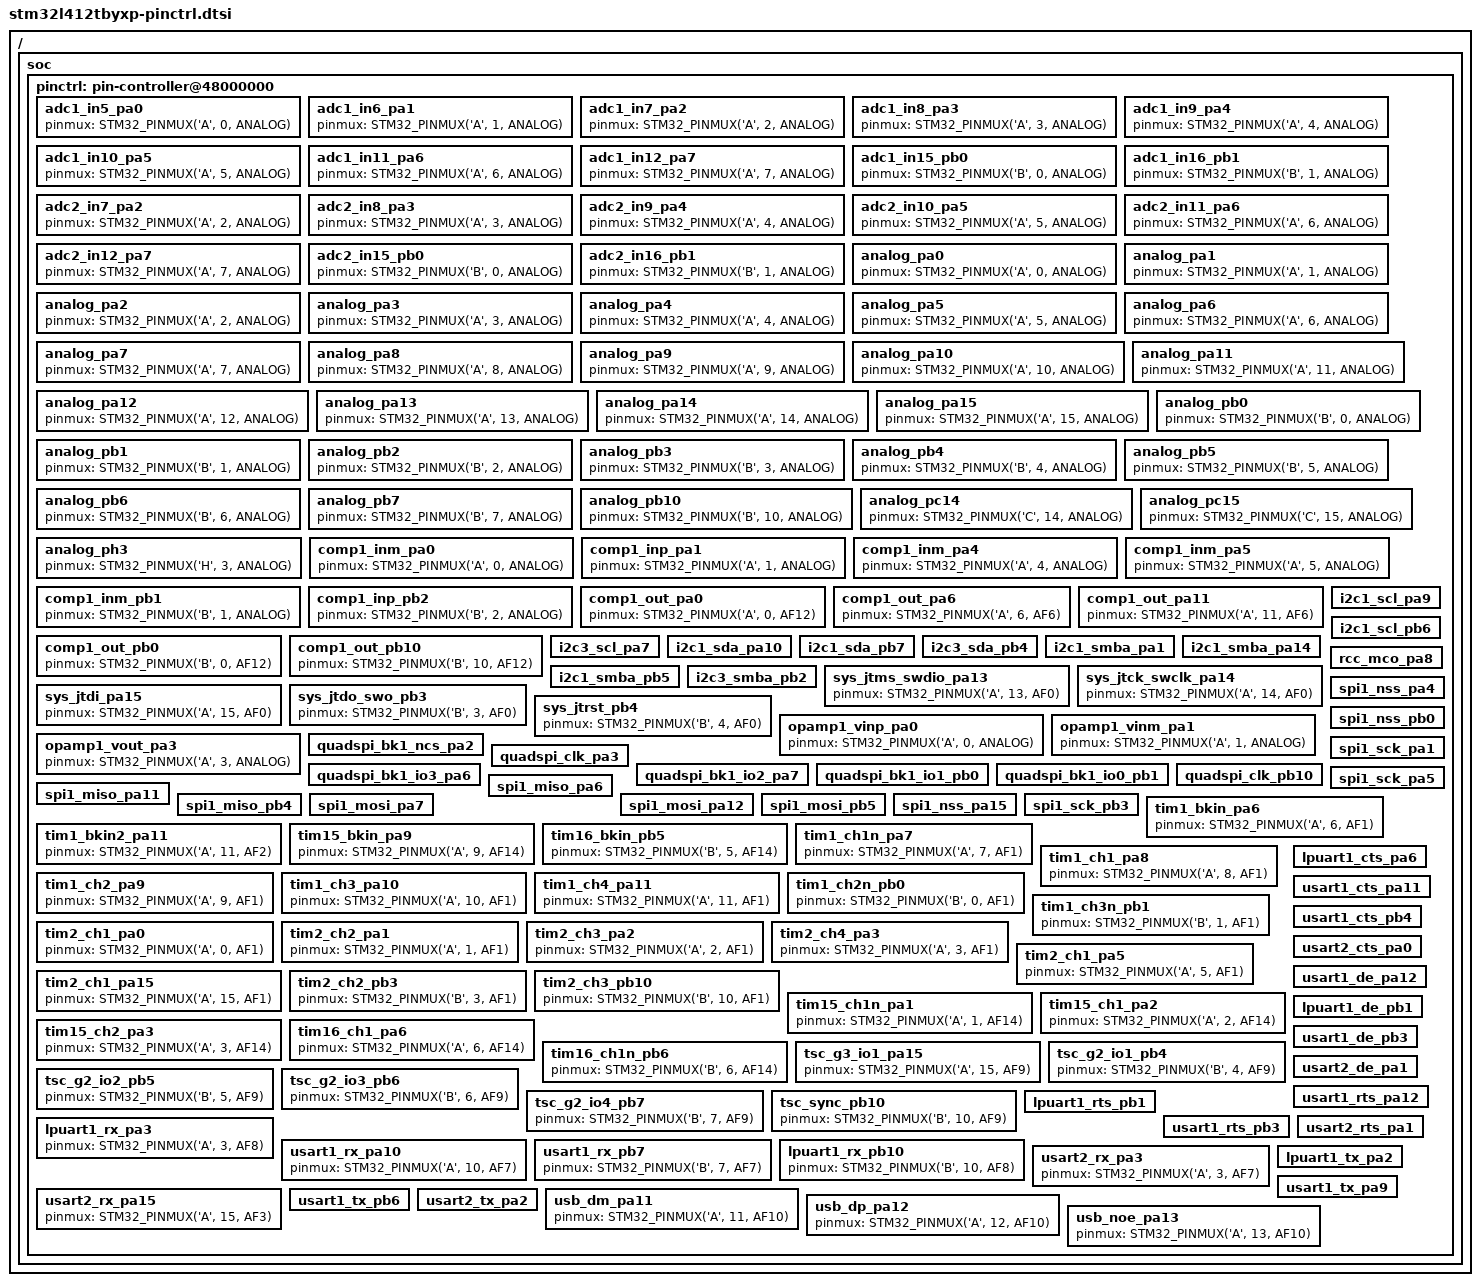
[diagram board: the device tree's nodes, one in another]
/*
 * NOTE: Autogenerated file using genpinctrl.py
 *
 * SPDX-License-Identifier: Apache-2.0
 */

#include <zephyr/dt-bindings/pinctrl/stm32-pinctrl.h>

/ {
	soc {
		pinctrl: pin-controller@48000000 {

			/* ADC_IN / ADC_INN / ADC_INP */

			/omit-if-no-ref/ adc1_in5_pa0: adc1_in5_pa0 {
				pinmux = <STM32_PINMUX('A', 0, ANALOG)>;
			};

			/omit-if-no-ref/ adc1_in6_pa1: adc1_in6_pa1 {
				pinmux = <STM32_PINMUX('A', 1, ANALOG)>;
			};

			/omit-if-no-ref/ adc1_in7_pa2: adc1_in7_pa2 {
				pinmux = <STM32_PINMUX('A', 2, ANALOG)>;
			};

			/omit-if-no-ref/ adc1_in8_pa3: adc1_in8_pa3 {
				pinmux = <STM32_PINMUX('A', 3, ANALOG)>;
			};

			/omit-if-no-ref/ adc1_in9_pa4: adc1_in9_pa4 {
				pinmux = <STM32_PINMUX('A', 4, ANALOG)>;
			};

			/omit-if-no-ref/ adc1_in10_pa5: adc1_in10_pa5 {
				pinmux = <STM32_PINMUX('A', 5, ANALOG)>;
			};

			/omit-if-no-ref/ adc1_in11_pa6: adc1_in11_pa6 {
				pinmux = <STM32_PINMUX('A', 6, ANALOG)>;
			};

			/omit-if-no-ref/ adc1_in12_pa7: adc1_in12_pa7 {
				pinmux = <STM32_PINMUX('A', 7, ANALOG)>;
			};

			/omit-if-no-ref/ adc1_in15_pb0: adc1_in15_pb0 {
				pinmux = <STM32_PINMUX('B', 0, ANALOG)>;
			};

			/omit-if-no-ref/ adc1_in16_pb1: adc1_in16_pb1 {
				pinmux = <STM32_PINMUX('B', 1, ANALOG)>;
			};

			/omit-if-no-ref/ adc2_in7_pa2: adc2_in7_pa2 {
				pinmux = <STM32_PINMUX('A', 2, ANALOG)>;
			};

			/omit-if-no-ref/ adc2_in8_pa3: adc2_in8_pa3 {
				pinmux = <STM32_PINMUX('A', 3, ANALOG)>;
			};

			/omit-if-no-ref/ adc2_in9_pa4: adc2_in9_pa4 {
				pinmux = <STM32_PINMUX('A', 4, ANALOG)>;
			};

			/omit-if-no-ref/ adc2_in10_pa5: adc2_in10_pa5 {
				pinmux = <STM32_PINMUX('A', 5, ANALOG)>;
			};

			/omit-if-no-ref/ adc2_in11_pa6: adc2_in11_pa6 {
				pinmux = <STM32_PINMUX('A', 6, ANALOG)>;
			};

			/omit-if-no-ref/ adc2_in12_pa7: adc2_in12_pa7 {
				pinmux = <STM32_PINMUX('A', 7, ANALOG)>;
			};

			/omit-if-no-ref/ adc2_in15_pb0: adc2_in15_pb0 {
				pinmux = <STM32_PINMUX('B', 0, ANALOG)>;
			};

			/omit-if-no-ref/ adc2_in16_pb1: adc2_in16_pb1 {
				pinmux = <STM32_PINMUX('B', 1, ANALOG)>;
			};

			/* Analog */

			/omit-if-no-ref/ analog_pa0: analog_pa0 {
				pinmux = <STM32_PINMUX('A', 0, ANALOG)>;
			};

			/omit-if-no-ref/ analog_pa1: analog_pa1 {
				pinmux = <STM32_PINMUX('A', 1, ANALOG)>;
			};

			/omit-if-no-ref/ analog_pa2: analog_pa2 {
				pinmux = <STM32_PINMUX('A', 2, ANALOG)>;
			};

			/omit-if-no-ref/ analog_pa3: analog_pa3 {
				pinmux = <STM32_PINMUX('A', 3, ANALOG)>;
			};

			/omit-if-no-ref/ analog_pa4: analog_pa4 {
				pinmux = <STM32_PINMUX('A', 4, ANALOG)>;
			};

			/omit-if-no-ref/ analog_pa5: analog_pa5 {
				pinmux = <STM32_PINMUX('A', 5, ANALOG)>;
			};

			/omit-if-no-ref/ analog_pa6: analog_pa6 {
				pinmux = <STM32_PINMUX('A', 6, ANALOG)>;
			};

			/omit-if-no-ref/ analog_pa7: analog_pa7 {
				pinmux = <STM32_PINMUX('A', 7, ANALOG)>;
			};

			/omit-if-no-ref/ analog_pa8: analog_pa8 {
				pinmux = <STM32_PINMUX('A', 8, ANALOG)>;
			};

			/omit-if-no-ref/ analog_pa9: analog_pa9 {
				pinmux = <STM32_PINMUX('A', 9, ANALOG)>;
			};

			/omit-if-no-ref/ analog_pa10: analog_pa10 {
				pinmux = <STM32_PINMUX('A', 10, ANALOG)>;
			};

			/omit-if-no-ref/ analog_pa11: analog_pa11 {
				pinmux = <STM32_PINMUX('A', 11, ANALOG)>;
			};

			/omit-if-no-ref/ analog_pa12: analog_pa12 {
				pinmux = <STM32_PINMUX('A', 12, ANALOG)>;
			};

			/omit-if-no-ref/ analog_pa13: analog_pa13 {
				pinmux = <STM32_PINMUX('A', 13, ANALOG)>;
			};

			/omit-if-no-ref/ analog_pa14: analog_pa14 {
				pinmux = <STM32_PINMUX('A', 14, ANALOG)>;
			};

			/omit-if-no-ref/ analog_pa15: analog_pa15 {
				pinmux = <STM32_PINMUX('A', 15, ANALOG)>;
			};

			/omit-if-no-ref/ analog_pb0: analog_pb0 {
				pinmux = <STM32_PINMUX('B', 0, ANALOG)>;
			};

			/omit-if-no-ref/ analog_pb1: analog_pb1 {
				pinmux = <STM32_PINMUX('B', 1, ANALOG)>;
			};

			/omit-if-no-ref/ analog_pb2: analog_pb2 {
				pinmux = <STM32_PINMUX('B', 2, ANALOG)>;
			};

			/omit-if-no-ref/ analog_pb3: analog_pb3 {
				pinmux = <STM32_PINMUX('B', 3, ANALOG)>;
			};

			/omit-if-no-ref/ analog_pb4: analog_pb4 {
				pinmux = <STM32_PINMUX('B', 4, ANALOG)>;
			};

			/omit-if-no-ref/ analog_pb5: analog_pb5 {
				pinmux = <STM32_PINMUX('B', 5, ANALOG)>;
			};

			/omit-if-no-ref/ analog_pb6: analog_pb6 {
				pinmux = <STM32_PINMUX('B', 6, ANALOG)>;
			};

			/omit-if-no-ref/ analog_pb7: analog_pb7 {
				pinmux = <STM32_PINMUX('B', 7, ANALOG)>;
			};

			/omit-if-no-ref/ analog_pb10: analog_pb10 {
				pinmux = <STM32_PINMUX('B', 10, ANALOG)>;
			};

			/omit-if-no-ref/ analog_pc14: analog_pc14 {
				pinmux = <STM32_PINMUX('C', 14, ANALOG)>;
			};

			/omit-if-no-ref/ analog_pc15: analog_pc15 {
				pinmux = <STM32_PINMUX('C', 15, ANALOG)>;
			};

			/omit-if-no-ref/ analog_ph3: analog_ph3 {
				pinmux = <STM32_PINMUX('H', 3, ANALOG)>;
			};

			/* COMP_IN */

			/omit-if-no-ref/ comp1_inm_pa0: comp1_inm_pa0 {
				pinmux = <STM32_PINMUX('A', 0, ANALOG)>;
			};

			/omit-if-no-ref/ comp1_inp_pa1: comp1_inp_pa1 {
				pinmux = <STM32_PINMUX('A', 1, ANALOG)>;
			};

			/omit-if-no-ref/ comp1_inm_pa4: comp1_inm_pa4 {
				pinmux = <STM32_PINMUX('A', 4, ANALOG)>;
			};

			/omit-if-no-ref/ comp1_inm_pa5: comp1_inm_pa5 {
				pinmux = <STM32_PINMUX('A', 5, ANALOG)>;
			};

			/omit-if-no-ref/ comp1_inm_pb1: comp1_inm_pb1 {
				pinmux = <STM32_PINMUX('B', 1, ANALOG)>;
			};

			/omit-if-no-ref/ comp1_inp_pb2: comp1_inp_pb2 {
				pinmux = <STM32_PINMUX('B', 2, ANALOG)>;
			};

			/* COMP_OUT */

			/omit-if-no-ref/ comp1_out_pa0: comp1_out_pa0 {
				pinmux = <STM32_PINMUX('A', 0, AF12)>;
			};

			/omit-if-no-ref/ comp1_out_pa6: comp1_out_pa6 {
				pinmux = <STM32_PINMUX('A', 6, AF6)>;
			};

			/omit-if-no-ref/ comp1_out_pa11: comp1_out_pa11 {
				pinmux = <STM32_PINMUX('A', 11, AF6)>;
			};

			/omit-if-no-ref/ comp1_out_pb0: comp1_out_pb0 {
				pinmux = <STM32_PINMUX('B', 0, AF12)>;
			};

			/omit-if-no-ref/ comp1_out_pb10: comp1_out_pb10 {
				pinmux = <STM32_PINMUX('B', 10, AF12)>;
			};

			/* I2C_SCL */

			/omit-if-no-ref/ i2c1_scl_pa9: i2c1_scl_pa9 {
				pinmux = <STM32_PINMUX('A', 9, AF4)>;
				bias-pull-up;
				drive-open-drain;
			};

			/omit-if-no-ref/ i2c1_scl_pb6: i2c1_scl_pb6 {
				pinmux = <STM32_PINMUX('B', 6, AF4)>;
				bias-pull-up;
				drive-open-drain;
			};

			/omit-if-no-ref/ i2c3_scl_pa7: i2c3_scl_pa7 {
				pinmux = <STM32_PINMUX('A', 7, AF4)>;
				bias-pull-up;
				drive-open-drain;
			};

			/* I2C_SDA */

			/omit-if-no-ref/ i2c1_sda_pa10: i2c1_sda_pa10 {
				pinmux = <STM32_PINMUX('A', 10, AF4)>;
				bias-pull-up;
				drive-open-drain;
			};

			/omit-if-no-ref/ i2c1_sda_pb7: i2c1_sda_pb7 {
				pinmux = <STM32_PINMUX('B', 7, AF4)>;
				bias-pull-up;
				drive-open-drain;
			};

			/omit-if-no-ref/ i2c3_sda_pb4: i2c3_sda_pb4 {
				pinmux = <STM32_PINMUX('B', 4, AF4)>;
				bias-pull-up;
				drive-open-drain;
			};

			/* I2C_SMBA */

			/omit-if-no-ref/ i2c1_smba_pa1: i2c1_smba_pa1 {
				pinmux = <STM32_PINMUX('A', 1, AF4)>;
				bias-pull-up;
			};

			/omit-if-no-ref/ i2c1_smba_pa14: i2c1_smba_pa14 {
				pinmux = <STM32_PINMUX('A', 14, AF4)>;
				bias-pull-up;
			};

			/omit-if-no-ref/ i2c1_smba_pb5: i2c1_smba_pb5 {
				pinmux = <STM32_PINMUX('B', 5, AF4)>;
				bias-pull-up;
			};

			/omit-if-no-ref/ i2c3_smba_pb2: i2c3_smba_pb2 {
				pinmux = <STM32_PINMUX('B', 2, AF4)>;
				bias-pull-up;
			};

			/* JTAG PORT */

			/omit-if-no-ref/ sys_jtms_swdio_pa13: sys_jtms_swdio_pa13 {
				pinmux = <STM32_PINMUX('A', 13, AF0)>;
			};

			/omit-if-no-ref/ sys_jtck_swclk_pa14: sys_jtck_swclk_pa14 {
				pinmux = <STM32_PINMUX('A', 14, AF0)>;
			};

			/omit-if-no-ref/ sys_jtdi_pa15: sys_jtdi_pa15 {
				pinmux = <STM32_PINMUX('A', 15, AF0)>;
			};

			/omit-if-no-ref/ sys_jtdo_swo_pb3: sys_jtdo_swo_pb3 {
				pinmux = <STM32_PINMUX('B', 3, AF0)>;
			};

			/omit-if-no-ref/ sys_jtrst_pb4: sys_jtrst_pb4 {
				pinmux = <STM32_PINMUX('B', 4, AF0)>;
			};

			/* OPAMP */

			/omit-if-no-ref/ opamp1_vinp_pa0: opamp1_vinp_pa0 {
				pinmux = <STM32_PINMUX('A', 0, ANALOG)>;
			};

			/omit-if-no-ref/ opamp1_vinm_pa1: opamp1_vinm_pa1 {
				pinmux = <STM32_PINMUX('A', 1, ANALOG)>;
			};

			/omit-if-no-ref/ opamp1_vout_pa3: opamp1_vout_pa3 {
				pinmux = <STM32_PINMUX('A', 3, ANALOG)>;
			};

			/* QUADSPI */

			/omit-if-no-ref/ quadspi_bk1_ncs_pa2: quadspi_bk1_ncs_pa2 {
				pinmux = <STM32_PINMUX('A', 2, AF10)>;
				slew-rate = "very-high-speed";
			};

			/omit-if-no-ref/ quadspi_clk_pa3: quadspi_clk_pa3 {
				pinmux = <STM32_PINMUX('A', 3, AF10)>;
				slew-rate = "very-high-speed";
			};

			/omit-if-no-ref/ quadspi_bk1_io3_pa6: quadspi_bk1_io3_pa6 {
				pinmux = <STM32_PINMUX('A', 6, AF10)>;
				slew-rate = "very-high-speed";
			};

			/omit-if-no-ref/ quadspi_bk1_io2_pa7: quadspi_bk1_io2_pa7 {
				pinmux = <STM32_PINMUX('A', 7, AF10)>;
				slew-rate = "very-high-speed";
			};

			/omit-if-no-ref/ quadspi_bk1_io1_pb0: quadspi_bk1_io1_pb0 {
				pinmux = <STM32_PINMUX('B', 0, AF10)>;
				slew-rate = "very-high-speed";
			};

			/omit-if-no-ref/ quadspi_bk1_io0_pb1: quadspi_bk1_io0_pb1 {
				pinmux = <STM32_PINMUX('B', 1, AF10)>;
				slew-rate = "very-high-speed";
			};

			/omit-if-no-ref/ quadspi_clk_pb10: quadspi_clk_pb10 {
				pinmux = <STM32_PINMUX('B', 10, AF10)>;
				slew-rate = "very-high-speed";
			};

			/* RCC_MCO */

			/omit-if-no-ref/ rcc_mco_pa8: rcc_mco_pa8 {
				pinmux = <STM32_PINMUX('A', 8, AF0)>;
				slew-rate = "very-high-speed";
			};

			/* SPI_MISO */

			/omit-if-no-ref/ spi1_miso_pa6: spi1_miso_pa6 {
				pinmux = <STM32_PINMUX('A', 6, AF5)>;
				bias-pull-down;
			};

			/omit-if-no-ref/ spi1_miso_pa11: spi1_miso_pa11 {
				pinmux = <STM32_PINMUX('A', 11, AF5)>;
				bias-pull-down;
			};

			/omit-if-no-ref/ spi1_miso_pb4: spi1_miso_pb4 {
				pinmux = <STM32_PINMUX('B', 4, AF5)>;
				bias-pull-down;
			};

			/* SPI_MOSI */

			/omit-if-no-ref/ spi1_mosi_pa7: spi1_mosi_pa7 {
				pinmux = <STM32_PINMUX('A', 7, AF5)>;
				bias-pull-down;
			};

			/omit-if-no-ref/ spi1_mosi_pa12: spi1_mosi_pa12 {
				pinmux = <STM32_PINMUX('A', 12, AF5)>;
				bias-pull-down;
			};

			/omit-if-no-ref/ spi1_mosi_pb5: spi1_mosi_pb5 {
				pinmux = <STM32_PINMUX('B', 5, AF5)>;
				bias-pull-down;
			};

			/* SPI_NSS */

			/omit-if-no-ref/ spi1_nss_pa4: spi1_nss_pa4 {
				pinmux = <STM32_PINMUX('A', 4, AF5)>;
				bias-pull-up;
			};

			/omit-if-no-ref/ spi1_nss_pa15: spi1_nss_pa15 {
				pinmux = <STM32_PINMUX('A', 15, AF5)>;
				bias-pull-up;
			};

			/omit-if-no-ref/ spi1_nss_pb0: spi1_nss_pb0 {
				pinmux = <STM32_PINMUX('B', 0, AF5)>;
				bias-pull-up;
			};

			/* SPI_SCK */

			/omit-if-no-ref/ spi1_sck_pa1: spi1_sck_pa1 {
				pinmux = <STM32_PINMUX('A', 1, AF5)>;
				bias-pull-down;
				slew-rate = "very-high-speed";
			};

			/omit-if-no-ref/ spi1_sck_pa5: spi1_sck_pa5 {
				pinmux = <STM32_PINMUX('A', 5, AF5)>;
				bias-pull-down;
				slew-rate = "very-high-speed";
			};

			/omit-if-no-ref/ spi1_sck_pb3: spi1_sck_pb3 {
				pinmux = <STM32_PINMUX('B', 3, AF5)>;
				bias-pull-down;
				slew-rate = "very-high-speed";
			};

			/* TIM_BKIN */

			/omit-if-no-ref/ tim1_bkin_pa6: tim1_bkin_pa6 {
				pinmux = <STM32_PINMUX('A', 6, AF1)>;
			};

			/omit-if-no-ref/ tim1_bkin2_pa11: tim1_bkin2_pa11 {
				pinmux = <STM32_PINMUX('A', 11, AF2)>;
			};

			/omit-if-no-ref/ tim15_bkin_pa9: tim15_bkin_pa9 {
				pinmux = <STM32_PINMUX('A', 9, AF14)>;
			};

			/omit-if-no-ref/ tim16_bkin_pb5: tim16_bkin_pb5 {
				pinmux = <STM32_PINMUX('B', 5, AF14)>;
			};

			/* TIM_CH / TIM_CHN */

			/omit-if-no-ref/ tim1_ch1n_pa7: tim1_ch1n_pa7 {
				pinmux = <STM32_PINMUX('A', 7, AF1)>;
			};

			/omit-if-no-ref/ tim1_ch1_pa8: tim1_ch1_pa8 {
				pinmux = <STM32_PINMUX('A', 8, AF1)>;
			};

			/omit-if-no-ref/ tim1_ch2_pa9: tim1_ch2_pa9 {
				pinmux = <STM32_PINMUX('A', 9, AF1)>;
			};

			/omit-if-no-ref/ tim1_ch3_pa10: tim1_ch3_pa10 {
				pinmux = <STM32_PINMUX('A', 10, AF1)>;
			};

			/omit-if-no-ref/ tim1_ch4_pa11: tim1_ch4_pa11 {
				pinmux = <STM32_PINMUX('A', 11, AF1)>;
			};

			/omit-if-no-ref/ tim1_ch2n_pb0: tim1_ch2n_pb0 {
				pinmux = <STM32_PINMUX('B', 0, AF1)>;
			};

			/omit-if-no-ref/ tim1_ch3n_pb1: tim1_ch3n_pb1 {
				pinmux = <STM32_PINMUX('B', 1, AF1)>;
			};

			/omit-if-no-ref/ tim2_ch1_pa0: tim2_ch1_pa0 {
				pinmux = <STM32_PINMUX('A', 0, AF1)>;
			};

			/omit-if-no-ref/ tim2_ch2_pa1: tim2_ch2_pa1 {
				pinmux = <STM32_PINMUX('A', 1, AF1)>;
			};

			/omit-if-no-ref/ tim2_ch3_pa2: tim2_ch3_pa2 {
				pinmux = <STM32_PINMUX('A', 2, AF1)>;
			};

			/omit-if-no-ref/ tim2_ch4_pa3: tim2_ch4_pa3 {
				pinmux = <STM32_PINMUX('A', 3, AF1)>;
			};

			/omit-if-no-ref/ tim2_ch1_pa5: tim2_ch1_pa5 {
				pinmux = <STM32_PINMUX('A', 5, AF1)>;
			};

			/omit-if-no-ref/ tim2_ch1_pa15: tim2_ch1_pa15 {
				pinmux = <STM32_PINMUX('A', 15, AF1)>;
			};

			/omit-if-no-ref/ tim2_ch2_pb3: tim2_ch2_pb3 {
				pinmux = <STM32_PINMUX('B', 3, AF1)>;
			};

			/omit-if-no-ref/ tim2_ch3_pb10: tim2_ch3_pb10 {
				pinmux = <STM32_PINMUX('B', 10, AF1)>;
			};

			/omit-if-no-ref/ tim15_ch1n_pa1: tim15_ch1n_pa1 {
				pinmux = <STM32_PINMUX('A', 1, AF14)>;
			};

			/omit-if-no-ref/ tim15_ch1_pa2: tim15_ch1_pa2 {
				pinmux = <STM32_PINMUX('A', 2, AF14)>;
			};

			/omit-if-no-ref/ tim15_ch2_pa3: tim15_ch2_pa3 {
				pinmux = <STM32_PINMUX('A', 3, AF14)>;
			};

			/omit-if-no-ref/ tim16_ch1_pa6: tim16_ch1_pa6 {
				pinmux = <STM32_PINMUX('A', 6, AF14)>;
			};

			/omit-if-no-ref/ tim16_ch1n_pb6: tim16_ch1n_pb6 {
				pinmux = <STM32_PINMUX('B', 6, AF14)>;
			};

			/* TSC */

			/omit-if-no-ref/ tsc_g3_io1_pa15: tsc_g3_io1_pa15 {
				pinmux = <STM32_PINMUX('A', 15, AF9)>;
			};

			/omit-if-no-ref/ tsc_g2_io1_pb4: tsc_g2_io1_pb4 {
				pinmux = <STM32_PINMUX('B', 4, AF9)>;
			};

			/omit-if-no-ref/ tsc_g2_io2_pb5: tsc_g2_io2_pb5 {
				pinmux = <STM32_PINMUX('B', 5, AF9)>;
			};

			/omit-if-no-ref/ tsc_g2_io3_pb6: tsc_g2_io3_pb6 {
				pinmux = <STM32_PINMUX('B', 6, AF9)>;
			};

			/omit-if-no-ref/ tsc_g2_io4_pb7: tsc_g2_io4_pb7 {
				pinmux = <STM32_PINMUX('B', 7, AF9)>;
			};

			/omit-if-no-ref/ tsc_sync_pb10: tsc_sync_pb10 {
				pinmux = <STM32_PINMUX('B', 10, AF9)>;
			};

			/* UART_CTS / USART_CTS / LPUART_CTS */

			/omit-if-no-ref/ lpuart1_cts_pa6: lpuart1_cts_pa6 {
				pinmux = <STM32_PINMUX('A', 6, AF8)>;
				bias-pull-up;
			};

			/omit-if-no-ref/ usart1_cts_pa11: usart1_cts_pa11 {
				pinmux = <STM32_PINMUX('A', 11, AF7)>;
				bias-pull-up;
			};

			/omit-if-no-ref/ usart1_cts_pb4: usart1_cts_pb4 {
				pinmux = <STM32_PINMUX('B', 4, AF7)>;
				bias-pull-up;
			};

			/omit-if-no-ref/ usart2_cts_pa0: usart2_cts_pa0 {
				pinmux = <STM32_PINMUX('A', 0, AF7)>;
				bias-pull-up;
			};

			/* UART_DE / USART_DE / LPUART_DE */

			/omit-if-no-ref/ usart1_de_pa12: usart1_de_pa12 {
				pinmux = <STM32_PINMUX('A', 12, AF7)>;
				drive-push-pull;
			};

			/omit-if-no-ref/ lpuart1_de_pb1: lpuart1_de_pb1 {
				pinmux = <STM32_PINMUX('B', 1, AF8)>;
				drive-push-pull;
			};

			/omit-if-no-ref/ usart1_de_pb3: usart1_de_pb3 {
				pinmux = <STM32_PINMUX('B', 3, AF7)>;
				drive-push-pull;
			};

			/omit-if-no-ref/ usart2_de_pa1: usart2_de_pa1 {
				pinmux = <STM32_PINMUX('A', 1, AF7)>;
				drive-push-pull;
			};

			/* UART_RTS / USART_RTS / LPUART_RTS */

			/omit-if-no-ref/ usart1_rts_pa12: usart1_rts_pa12 {
				pinmux = <STM32_PINMUX('A', 12, AF7)>;
				drive-push-pull;
			};

			/omit-if-no-ref/ lpuart1_rts_pb1: lpuart1_rts_pb1 {
				pinmux = <STM32_PINMUX('B', 1, AF8)>;
				drive-push-pull;
			};

			/omit-if-no-ref/ usart1_rts_pb3: usart1_rts_pb3 {
				pinmux = <STM32_PINMUX('B', 3, AF7)>;
				drive-push-pull;
			};

			/omit-if-no-ref/ usart2_rts_pa1: usart2_rts_pa1 {
				pinmux = <STM32_PINMUX('A', 1, AF7)>;
				drive-push-pull;
			};

			/* UART_RX / USART_RX / LPUART_RX */

			/omit-if-no-ref/ lpuart1_rx_pa3: lpuart1_rx_pa3 {
				pinmux = <STM32_PINMUX('A', 3, AF8)>;
			};

			/omit-if-no-ref/ usart1_rx_pa10: usart1_rx_pa10 {
				pinmux = <STM32_PINMUX('A', 10, AF7)>;
			};

			/omit-if-no-ref/ usart1_rx_pb7: usart1_rx_pb7 {
				pinmux = <STM32_PINMUX('B', 7, AF7)>;
			};

			/omit-if-no-ref/ lpuart1_rx_pb10: lpuart1_rx_pb10 {
				pinmux = <STM32_PINMUX('B', 10, AF8)>;
			};

			/omit-if-no-ref/ usart2_rx_pa3: usart2_rx_pa3 {
				pinmux = <STM32_PINMUX('A', 3, AF7)>;
			};

			/omit-if-no-ref/ usart2_rx_pa15: usart2_rx_pa15 {
				pinmux = <STM32_PINMUX('A', 15, AF3)>;
			};

			/* UART_TX / USART_TX / LPUART_TX */

			/omit-if-no-ref/ lpuart1_tx_pa2: lpuart1_tx_pa2 {
				pinmux = <STM32_PINMUX('A', 2, AF8)>;
				bias-pull-up;
			};

			/omit-if-no-ref/ usart1_tx_pa9: usart1_tx_pa9 {
				pinmux = <STM32_PINMUX('A', 9, AF7)>;
				bias-pull-up;
			};

			/omit-if-no-ref/ usart1_tx_pb6: usart1_tx_pb6 {
				pinmux = <STM32_PINMUX('B', 6, AF7)>;
				bias-pull-up;
			};

			/omit-if-no-ref/ usart2_tx_pa2: usart2_tx_pa2 {
				pinmux = <STM32_PINMUX('A', 2, AF7)>;
				bias-pull-up;
			};

			/* USB */

			/omit-if-no-ref/ usb_dm_pa11: usb_dm_pa11 {
				pinmux = <STM32_PINMUX('A', 11, AF10)>;
			};

			/omit-if-no-ref/ usb_dp_pa12: usb_dp_pa12 {
				pinmux = <STM32_PINMUX('A', 12, AF10)>;
			};

			/omit-if-no-ref/ usb_noe_pa13: usb_noe_pa13 {
				pinmux = <STM32_PINMUX('A', 13, AF10)>;
			};

		};
	};
};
